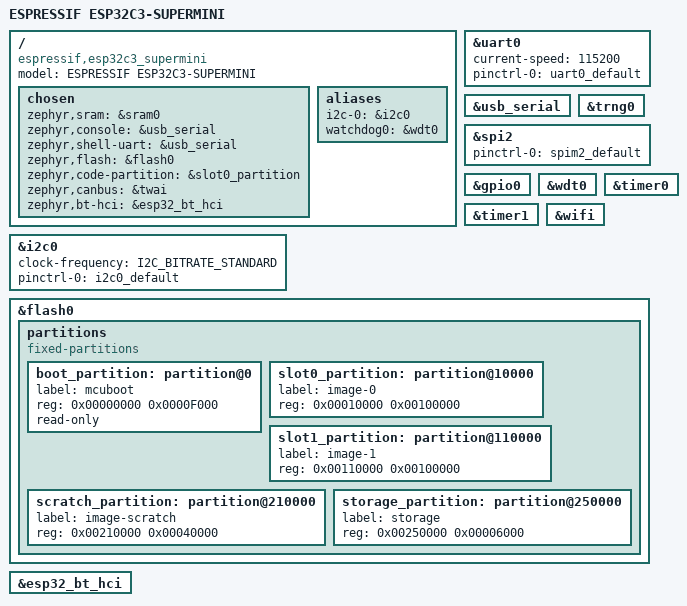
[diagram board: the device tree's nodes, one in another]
/*
 * Copyright 2022 Google LLC
 *
 * SPDX-License-Identifier: Apache-2.0
 */

 /dts-v1/;

#include <espressif/esp32c3/esp32c3_fx4.dtsi>
#include "esp32c3_supermini-pinctrl.dtsi"


/ {
	model = "ESPRESSIF ESP32C3-SUPERMINI";
	compatible = "espressif,esp32c3_supermini";

	chosen {
		zephyr,sram = &sram0;
		zephyr,console = &usb_serial;
		zephyr,shell-uart = &usb_serial;
		zephyr,flash = &flash0;
		zephyr,code-partition = &slot0_partition;
		zephyr,canbus = &twai;
		zephyr,bt-hci = &esp32_bt_hci;
	};

	aliases {
		i2c-0 = &i2c0;
		watchdog0 = &wdt0;
	};
};

&uart0 {
	status = "okay";
	current-speed = <115200>;
	pinctrl-0 = <&uart0_default>;
	pinctrl-names = "default";
};

&usb_serial {
	status = "okay";
};

&i2c0 {
	status = "okay";
	clock-frequency = <I2C_BITRATE_STANDARD>;
	pinctrl-0 = <&i2c0_default>;
	pinctrl-names = "default";
};

&trng0 {
	status = "okay";
};

&spi2 {
	#address-cells = <1>;
	#size-cells = <0>;
	status = "okay";
	pinctrl-0 = <&spim2_default>;
	pinctrl-names = "default";
};

&gpio0 {
	status = "okay";
};

&wdt0 {
	status = "okay";
};

&timer0 {
	status = "okay";
};

&timer1 {
	status = "okay";
};

&wifi {
	status = "okay";
};

&flash0 {
	status = "okay";
	partitions {
		compatible = "fixed-partitions";
		#address-cells = <1>;
		#size-cells = <1>;

		/* Reserve 60kB for the bootloader */
		boot_partition: partition@0 {
			label = "mcuboot";
			reg = <0x00000000 0x0000F000>;
			read-only;
		};

		/* Reserve 1024kB for the application in slot 0 */
		slot0_partition: partition@10000 {
			label = "image-0";
			reg = <0x00010000 0x00100000>;
		};

		/* Reserve 1024kB for the application in slot 1 */
		slot1_partition: partition@110000 {
			label = "image-1";
			reg = <0x00110000 0x00100000>;
		};

		/* Reserve 256kB for the scratch partition */
		scratch_partition: partition@210000 {
			   label = "image-scratch";
			   reg = <0x00210000 0x00040000>;
		};

		storage_partition: partition@250000 {
			label = "storage";
			reg = <0x00250000 0x00006000>;
		};
	};
};

&esp32_bt_hci {
	status = "okay";
};
